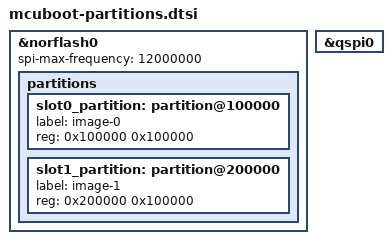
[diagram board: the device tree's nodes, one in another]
/* SPDX-License-Identifier: Apache-2.0 */
/delete-node/ &os_partition;
&norflash0 {
	partitions {
		slot0_partition: partition@100000 {
			label = "image-0";
			reg = <0x100000 0x100000>;
		};
		slot1_partition: partition@200000 {
			label = "image-1";
			reg = <0x200000 0x100000>;
		};
	};
};
&qspi0 { status = "okay"; };
&norflash0 { spi-max-frequency = <12000000>; };
